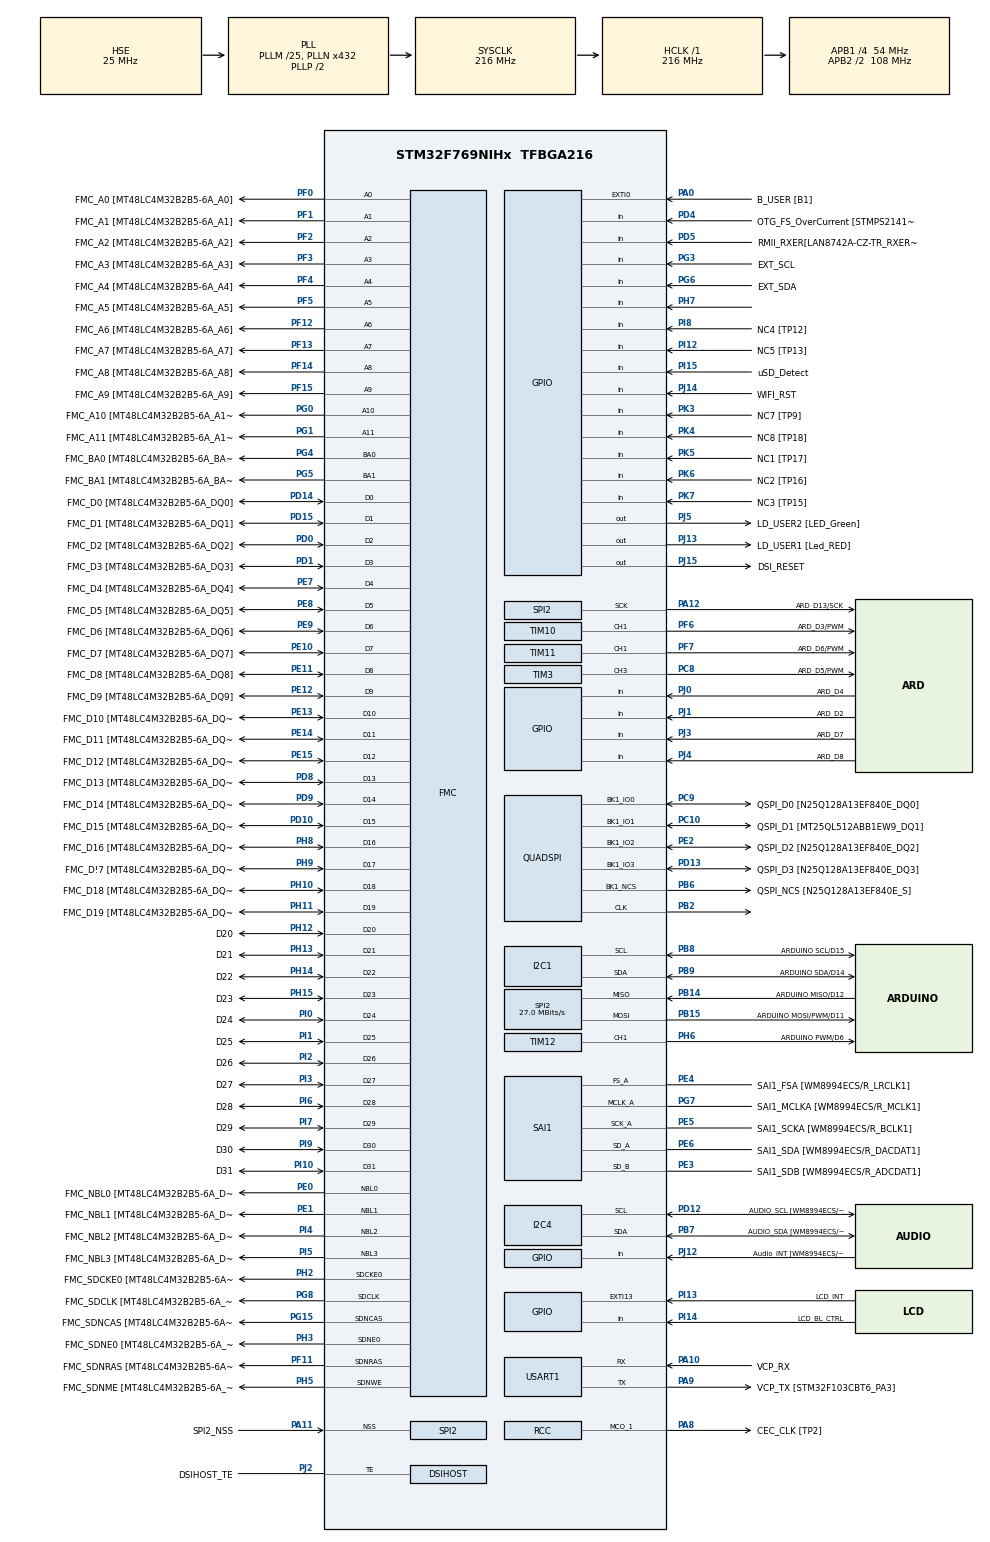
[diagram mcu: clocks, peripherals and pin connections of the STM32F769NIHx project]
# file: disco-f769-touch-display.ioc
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DSIHOST.CommandSize=400
DSIHOST.LPDcsLongWrite=DSI_LP_DLW_ENABLE
DSIHOST.LPDcsShortReadNoP=DSI_LP_DSR0P_ENABLE
DSIHOST.LPDcsShortWriteNoP=DSI_LP_DSW0P_ENABLE
DSIHOST.LPDcsShortWriteOneP=DSI_LP_DSW1P_ENABLE
DSIHOST.LPGenLongWrite=DSI_LP_GLW_ENABLE
DSIHOST.LPGenShortReadNoP=DSI_LP_GSR0P_ENABLE
DSIHOST.LPGenShortReadOneP=DSI_LP_GSR1P_ENABLE
DSIHOST.LPGenShortReadTwoP=DSI_LP_GSR2P_ENABLE
DSIHOST.LPGenShortWriteNoP=DSI_LP_GSW0P_ENABLE
DSIHOST.LPGenShortWriteOneP=DSI_LP_GSW1P_ENABLE
DSIHOST.LPGenShortWriteTwoP=DSI_LP_GSW2P_ENABLE
DSIHOST.LPMaxReadPacket=DSI_LP_MRDP_ENABLE
DSIHOST.NumberOfLanes=DSI_TWO_DATA_LANES
DSIHOST.StopWaitTime=10
DSIHOST.TEAcknowledgeRequest=DSI_TE_ACKNOWLEDGE_ENABLE
DSIHOST_CKN.GPIO_Label=DSI_CK_N
DSIHOST_CKN.Mode=DSIHost_Adapted_TE
DSIHOST_CKN.Signal=DSIHOST_CKN
DSIHOST_CKP.GPIO_Label=DSI_CK_P
DSIHOST_CKP.Mode=DSIHost_Adapted_TE
DSIHOST_CKP.Signal=DSIHOST_CKP
DSIHOST_D0N.GPIO_Label=DSI_D0_N
DSIHOST_D0N.Mode=DSIHost_Adapted_TE
DSIHOST_D0N.Signal=DSIHOST_D0N
DSIHOST_D0P.GPIO_Label=DSI_D0_p
DSIHOST_D0P.Mode=DSIHost_Adapted_TE
DSIHOST_D0P.Signal=DSIHOST_D0P
DSIHOST_D1N.GPIO_Label=DSI_D1_N
DSIHOST_D1N.Mode=DSIHost_Adapted_TE
DSIHOST_D1N.Signal=DSIHOST_D1N
DSIHOST_D1P.GPIO_Label=DSI_D1_P
DSIHOST_D1P.Mode=DSIHost_Adapted_TE
DSIHOST_D1P.Signal=DSIHOST_D1P
FMC.CASLatency1=FMC_SDRAM_CAS_LATENCY_3
FMC.ExitSelfRefreshDelay1=7
FMC.LoadToActiveDelay1=2
FMC.RCDDelay1=2
FMC.RPDelay1=2
FMC.RPDelay2=2
FMC.ReadBurst1=FMC_SDRAM_RBURST_ENABLE
FMC.ReadBurst2=FMC_SDRAM_RBURST_ENABLE
FMC.RowCycleDelay1=7
FMC.RowCycleDelay2=7
FMC.SDClockPeriod1=FMC_SDRAM_CLOCK_PERIOD_2
FMC.SDClockPeriod2=FMC_SDRAM_CLOCK_PERIOD_2
FMC.SelfRefreshTime1=4
FMC.WriteRecoveryTime1=3
I2C1.Timing=0x20404768
I2C4.Timing=0x20404768
LTDC.ActiveW=200
LTDC.Alpha_L0=255
LTDC.BlendingFactor1_L0=LTDC_BLENDING_FACTOR1_PAxCA
LTDC.BlendingFactor2_L0=LTDC_BLENDING_FACTOR2_PAxCA
LTDC.FBStartAdress_L0=0xC0000000
LTDC.HBP=1
LTDC.HFP=1
LTDC.HSync=1
LTDC.ImageHeight_L0=480
LTDC.ImageWidth_L0=200
LTDC.Layers=0
LTDC.PixelFormat_L0=LTDC_PIXEL_FORMAT_RGB565
LTDC.VBP=1
LTDC.VFP=1
LTDC.VSync=1
LTDC.WindowX1_L0=200
LTDC.WindowY1_L0=480
Mcu.Family=STM32F7
Mcu.Name=STM32F769NIHx
Mcu.Package=TFBGA216
NVIC.DMA2D_IRQn=true\:0\:0\:false\:false\:true\:true\:true\:true
NVIC.DSI_IRQn=true\:0\:0\:false\:false\:true\:true\:true\:true
NVIC.LTDC_IRQn=true\:0\:0\:false\:false\:true\:true\:true\:true
NVIC.PriorityGroup=NVIC_PRIORITYGROUP_4
NVIC.TIM6_DAC_IRQn=true\:15\:0\:false\:false\:true\:false\:true\:true
NVIC.TimeBase=TIM6_DAC_IRQn
NVIC.TimeBaseIP=TIM6
PA0/WKUP.GPIO_Label=B_USER [B1]
PA0/WKUP.Signal=GPXTI0
PA1.GPIO_Label=RMII_REF_CLK [LAN8742A-CZ-TR_REFCLK0]
PA1.Signal=ETH_REF_CLK
PA10.GPIO_Label=VCP_RX 
PA10.Mode=Asynchronous
PA10.Signal=USART1_RX
PA11.GPIO_Label=SPI2_NSS
PA11.Mode=NSS_Signal_Hard_Input
PA11.Signal=SPI2_NSS
PA12.GPIO_Label=ARD_D13/SCK
PA12.GPIO_Mode=GPIO_MODE_AF_PP
PA12.GPIO_PuPd=GPIO_NOPULL
PA12.GPIO_Speed=GPIO_SPEED_FREQ_LOW
PA12.Mode=Full_Duplex_Master
PA12.Signal=SPI2_SCK
PA13.GPIO_Label=SWDIO
PA13.Mode=Serial_Wire
PA13.Signal=SYS_JTMS-SWDIO
PA14.GPIO_Label=SWCLK
PA14.Mode=Serial_Wire
PA14.Signal=SYS_JTCK-SWCLK
PA15.GPIO_Label=CEC
PA15.Signal=CEC
PA2.GPIO_Label=RMII_MDIO [LAN8742A-CZ-TR_MDIO]
PA2.Signal=ETH_MDIO
PA3.GPIO_Label=ULPI_D0 [USB3320C-EZK_D0]
PA3.Signal=USB_OTG_HS_ULPI_D0
PA4.GPIO_Label=ARD_A1
PA4.Signal=ADCx_IN4
PA5.GPIO_Label=ULPI_CLK [USB3320C-EZK_CLKOUT]
PA5.Signal=USB_OTG_HS_ULPI_CK
PA6.GPIO_Label=ARD_A0
PA6.Signal=ADCx_IN6
PA7.GPIO_Label=RMII_CRS_DV [LAN8742A-CZ-TR_CRS_DV]
PA7.Signal=ETH_CRS_DV
PA8.GPIO_Label=CEC_CLK [TP2]
PA8.Mode=Clock-out-1
PA8.Signal=RCC_MCO_1
PA9.GPIO_Label=VCP_TX [STM32F103CBT6_PA3]
PA9.GPIO_Mode=GPIO_MODE_AF_PP
PA9.GPIO_PuPd=GPIO_NOPULL
PA9.GPIO_Speed=GPIO_SPEED_FREQ_LOW
PA9.Mode=Asynchronous
PA9.Signal=USART1_TX
PB0.GPIO_Label=ULPI_D1 [USB3320C-EZK_D1]
PB0.Signal=USB_OTG_HS_ULPI_D1
PB1.GPIO_Label=ULPI_D2 [USB3320C-EZK_D2]
PB1.Signal=USB_OTG_HS_ULPI_D2
PB10.GPIO_Label=ULPI_D3 [USB3320C-EZK_D3]
PB10.Signal=USB_OTG_HS_ULPI_D3
PB11.GPIO_Label=ULPI_D4 [USB3320C-EZK_D4]
PB11.Signal=USB_OTG_HS_ULPI_D4
PB12.GPIO_Label=ULPI_D5 [USB3320C-EZK_D5]
PB12.Signal=USB_OTG_HS_ULPI_D5
PB13.GPIO_Label=ULPI_D6 [USB3320C-EZK_D6]
PB13.Signal=USB_OTG_HS_ULPI_D6
PB14.GPIO_Label=ARDUINO MISO/D12
PB14.GPIO_Mode=GPIO_MODE_AF_PP
PB14.GPIO_PuPd=GPIO_NOPULL
PB14.GPIO_Speed=GPIO_SPEED_FREQ_LOW
PB14.Mode=Full_Duplex_Master
PB14.Signal=SPI2_MISO
PB15.GPIO_Label=ARDUINO MOSI/PWM/D11
PB15.GPIO_Mode=GPIO_MODE_AF_PP
PB15.GPIO_PuPd=GPIO_NOPULL
PB15.GPIO_Speed=GPIO_SPEED_FREQ_LOW
PB15.Mode=Full_Duplex_Master
PB15.Signal=SPI2_MOSI
PB2.Mode=Single Bank 1
PB2.Signal=QUADSPI_CLK
PB3.GPIO_Label=uSD_D2
PB3.Signal=SDMMC2_D2
PB4.GPIO_Label=uSD_D3
PB4.Signal=SDMMC2_D3
PB5.GPIO_Label=ULPI_D7 [USB3320C-EZK_D7]
PB5.Signal=USB_OTG_HS_ULPI_D7
PB6.GPIO_Label=QSPI_NCS [N25Q128A13EF840E_S]
PB6.Mode=Single Bank 1
PB6.Signal=QUADSPI_BK1_NCS
PB7.GPIO_Label=AUDIO_SDA [WM8994ECS/R_SDA]
PB7.GPIO_Pu=GPIO_PULLUP
PB7.Mode=I2C
PB7.Signal=I2C4_SDA
PB8.GPIO_Label=ARDUINO SCL/D15
PB8.GPIO_Mode=GPIO_MODE_AF_OD
PB8.GPIO_Pu=GPIO_PULLUP
PB8.GPIO_PuPd=GPIO_NOPULL
PB8.GPIO_Speed=GPIO_SPEED_FREQ_LOW
PB8.Mode=I2C
PB8.Signal=I2C1_SCL
PB9.GPIO_Label=ARDUINO SDA/D14
PB9.GPIO_Mode=GPIO_MODE_AF_OD
PB9.GPIO_Pu=GPIO_PULLUP
PB9.GPIO_PuPd=GPIO_NOPULL
PB9.GPIO_Speed=GPIO_SPEED_FREQ_LOW
PB9.Mode=I2C
PB9.Signal=I2C1_SDA
PC0.GPIO_Label=ULPI_STP [USB3320C-EZK_STP]
PC0.Signal=USB_OTG_HS_ULPI_STP
PC1.GPIO_Label=RMII_MDC [LAN8742A-CZ-TR_MDC]
PC1.Signal=ETH_MDC
PC10.GPIO_Label=QSPI_D1 [MT25QL512ABB1EW9_DQ1]
PC10.Mode=Single Bank 1
PC10.Signal=QUADSPI_BK1_IO1
PC11.GPIO_Label=DFSDM_DATIN5 [TP5]
PC11.Signal=S_DATAIN5DFSDM1
PC12.GPIO_Label=WIFI_RX
PC12.Signal=UART5_TX
PC13.Signal=RTC_OUT
PC14/OSC32_IN.GPIO_Label=RCC_OSC32_IN
PC14/OSC32_IN.Mode=LSE-External-Oscillator
PC14/OSC32_IN.Signal=RCC_OSC32_IN
PC15/OSC32_OUT.GPIO_Label=RCC_OSC32_OUT
PC15/OSC32_OUT.Mode=LSE-External-Oscillator
PC15/OSC32_OUT.Signal=RCC_OSC32_OUT
PC2.GPIO_Label=ARD_A2
PC2.Signal=ADCx_IN12
PC4.GPIO_Label=RMII_RXD0 [LAN8742A-CZ-TR_RXD0]
PC4.Signal=ETH_RXD0
PC5.GPIO_Label=RMII_RXD1 [LAN8742A-CZ-TR_RXD1]
PC5.Signal=ETH_RXD1
PC6.GPIO_Label=ARDUINO TX/D1
PC6.Signal=USART6_TX
PC7.GPIO_Label=ARD_D0/RX
PC7.Signal=USART6_RX
PC8.GPIO_Label=ARD_D5/PWM
PC8.Signal=S_TIM3_CH3
PC9.GPIO_Label=QSPI_D0 [N25Q128A13EF840E_DQ0]
PC9.Mode=Single Bank 1
PC9.Signal=QUADSPI_BK1_IO0
PD0.GPIO_Label=FMC_D2 [MT48LC4M32B2B5-6A_DQ2]
PD0.Signal=FMC_D2_DA2
PD1.GPIO_Label=FMC_D3 [MT48LC4M32B2B5-6A_DQ3]
PD1.Signal=FMC_D3_DA3
PD10.GPIO_Label=FMC_D15 [MT48LC4M32B2B5-6A_DQ15]
PD10.Signal=FMC_D15_DA15
PD11.GPIO_Label=SPDIF_TX [TP20]
PD11.Signal=SAI2_SD_A
PD12.GPIO_Label=AUDIO_SCL [WM8994ECS/R_SCLK]
PD12.GPIO_Pu=GPIO_PULLUP
PD12.Mode=I2C
PD12.Signal=I2C4_SCL
PD13.GPIO_Label=QSPI_D3 [N25Q128A13EF840E_DQ3]
PD13.Mode=Single Bank 1
PD13.Signal=QUADSPI_BK1_IO3
PD14.GPIO_Label=FMC_D0 [MT48LC4M32B2B5-6A_DQ0]
PD14.Signal=FMC_D0_DA0
PD15.GPIO_Label=FMC_D1 [MT48LC4M32B2B5-6A_DQ1]
PD15.Signal=FMC_D1_DA1
PD2.GPIO_Label=WIFI_TX
PD2.Signal=UART5_RX
PD3.GPIO_Label=DFSDM_CKOUT [TP102]
PD3.Signal=S_CKOUTDFSDM1
PD4.GPIO_Label=OTG_FS_OverCurrent [STMPS2141STR_Fault]
PD4.Signal=GPIO_Input
PD5.GPIO_Label=RMII_RXER[LAN8742A-CZ-TR_RXERR]
PD5.Signal=GPIO_Input
PD6.GPIO_Label=uSD_CLK
PD6.Signal=SDMMC2_CK
PD7.GPIO_Label=uSD_CMD
PD7.Signal=SDMMC2_CMD
PD8.GPIO_Label=FMC_D13 [MT48LC4M32B2B5-6A_DQ13]
PD8.Signal=FMC_D13_DA13
PD9.GPIO_Label=FMC_D14 [MT48LC4M32B2B5-6A_DQ14]
PD9.Signal=FMC_D14_DA14
PE0.GPIO_Label=FMC_NBL0 [MT48LC4M32B2B5-6A_DQM0]
PE0.Signal=FMC_NBL0
PE1.GPIO_Label=FMC_NBL1 [MT48LC4M32B2B5-6A_DQM1]
PE1.Signal=FMC_NBL1
PE10.GPIO_Label=FMC_D7 [MT48LC4M32B2B5-6A_DQ7]
PE10.Signal=FMC_D7_DA7
PE11.GPIO_Label=FMC_D8 [MT48LC4M32B2B5-6A_DQ8]
PE11.Signal=FMC_D8_DA8
PE12.GPIO_Label=FMC_D9 [MT48LC4M32B2B5-6A_DQ9]
PE12.Signal=FMC_D9_DA9
PE13.GPIO_Label=FMC_D10 [MT48LC4M32B2B5-6A_DQ10]
PE13.Signal=FMC_D10_DA10
PE14.GPIO_Label=FMC_D11 [MT48LC4M32B2B5-6A_DQ11]
PE14.Signal=FMC_D11_DA11
PE15.GPIO_Label=FMC_D12 [MT48LC4M32B2B5-6A_DQ12]
PE15.Signal=FMC_D12_DA12
PE2.GPIO_Label=QSPI_D2 [N25Q128A13EF840E_DQ2]
PE2.Mode=Single Bank 1
PE2.Signal=QUADSPI_BK1_IO2
PE3.GPIO_Label=SAI1_SDB [WM8994ECS/R_ADCDAT1]
PE3.Mode=SAI_B_SyncSlave
PE3.Signal=SAI1_SD_B
PE4.GPIO_Label=SAI1_FSA [WM8994ECS/R_LRCLK1]
PE4.Mode=SAI_A_MasterWithClock
PE4.Signal=SAI1_FS_A
PE5.GPIO_Label=SAI1_SCKA [WM8994ECS/R_BCLK1]
PE5.Mode=SAI_A_MasterWithClock
PE5.Signal=SAI1_SCK_A
PE6.GPIO_Label=SAI1_SDA [WM8994ECS/R_DACDAT1]
PE6.Mode=SAI_A_MasterWithClock
PE6.Signal=SAI1_SD_A
PE7.GPIO_Label=FMC_D4 [MT48LC4M32B2B5-6A_DQ4]
PE7.Signal=FMC_D4_DA4
PE8.GPIO_Label=FMC_D5 [MT48LC4M32B2B5-6A_DQ5]
PE8.Signal=FMC_D5_DA5
PE9.GPIO_Label=FMC_D6 [MT48LC4M32B2B5-6A_DQ6]
PE9.Signal=FMC_D6_DA6
PF0.GPIO_Label=FMC_A0 [MT48LC4M32B2B5-6A_A0]
PF0.Signal=FMC_A0
PF1.GPIO_Label=FMC_A1 [MT48LC4M32B2B5-6A_A1]
PF1.Signal=FMC_A1
PF10.GPIO_Label=ARDUINO A1
PF10.GPIO_Mode=GPIO_MODE_ANALOG
PF10.GPIO_PuPd=GPIO_NOPULL
PF10.Signal=ADC3_IN8
PF11.GPIO_Label=FMC_SDNRAS [MT48LC4M32B2B5-6A_RAS]
PF11.Signal=FMC_SDNRAS
PF12.GPIO_Label=FMC_A6 [MT48LC4M32B2B5-6A_A6]
PF12.Signal=FMC_A6
PF13.GPIO_Label=FMC_A7 [MT48LC4M32B2B5-6A_A7]
PF13.Signal=FMC_A7
PF14.GPIO_Label=FMC_A8 [MT48LC4M32B2B5-6A_A8]
PF14.Signal=FMC_A8
PF15.GPIO_Label=FMC_A9 [MT48LC4M32B2B5-6A_A9]
PF15.Signal=FMC_A9
PF2.GPIO_Label=FMC_A2 [MT48LC4M32B2B5-6A_A2]
PF2.Signal=FMC_A2
PF3.GPIO_Label=FMC_A3 [MT48LC4M32B2B5-6A_A3]
PF3.Signal=FMC_A3
PF4.GPIO_Label=FMC_A4 [MT48LC4M32B2B5-6A_A4]
PF4.Signal=FMC_A4
PF5.GPIO_Label=FMC_A5 [MT48LC4M32B2B5-6A_A5]
PF5.Signal=FMC_A5
PF6.GPIO_Label=ARD_D3/PWM
PF6.Signal=S_TIM10_CH1
PF7.GPIO_Label=ARD_D6/PWM
PF7.Signal=S_TIM11_CH1
PF8.GPIO_Label=ARDUINO A3
PF8.GPIO_Mode=GPIO_MODE_ANALOG
PF8.GPIO_PuPd=GPIO_NOPULL
PF8.Signal=ADC3_IN6
PF9.GPIO_Label=ARDUINO A2
PF9.GPIO_Mode=GPIO_MODE_ANALOG
PF9.GPIO_PuPd=GPIO_NOPULL
PF9.Signal=ADC3_IN7
PG0.GPIO_Label=FMC_A10 [MT48LC4M32B2B5-6A_A10]
PG0.Signal=FMC_A10
PG1.GPIO_Label=FMC_A11 [MT48LC4M32B2B5-6A_A11]
PG1.Signal=FMC_A11
PG10.GPIO_Label=uSD_D1
PG10.Signal=SDMMC2_D1
PG11.GPIO_Label=RMII_TX_EN [LAN8742A-CZ-TR_TXEN]
PG11.Signal=ETH_TX_EN
PG12.GPIO_Label=SPDIF_RX [74LVC1G04SE_4]
PG12.Signal=SPDIFRX_IN1
PG13.GPIO_Label=RMII_TXD0 [LAN8742A-CZ-TR_TXD0]
PG13.Signal=ETH_TXD0
PG14.GPIO_Label=RMII_TXD1 [LAN8742A-CZ-TR_TXD1]
PG14.Signal=ETH_TXD1
PG15.GPIO_Label=FMC_SDNCAS [MT48LC4M32B2B5-6A_CAS]
PG15.Signal=FMC_SDNCAS
PG2.GPIO_Label=FMC_A12
PG2.Signal=FMC_A12
PG3.GPIO_Label=EXT_SCL
PG3.Signal=GPIO_Input
PG4.GPIO_Label=FMC_BA0 [MT48LC4M32B2B5-6A_BA0]
PG4.Signal=FMC_A14_BA0
PG5.GPIO_Label=FMC_BA1 [MT48LC4M32B2B5-6A_BA1]
PG5.Signal=FMC_A15_BA1
PG6.GPIO_Label=EXT_SDA
PG6.Signal=GPIO_Input
PG7.GPIO_Label=SAI1_MCLKA [WM8994ECS/R_MCLK1]
PG7.Mode=SAI_A_MasterWithClock
PG7.Signal=SAI1_MCLK_A
PG8.GPIO_Label=FMC_SDCLK [MT48LC4M32B2B5-6A_CLK]
PG8.Signal=FMC_SDCLK
PG9.GPIO_Label=uSD_D0
PG9.Signal=SDMMC2_D0
PH0/OSC_IN.GPIO_Label=OSC_25M [NZ2520SB-25.00M_OUT]
PH0/OSC_IN.Mode=HSE-External-Oscillator
PH0/OSC_IN.Signal=RCC_OSC_IN
PH1/OSC_OUT.Mode=HSE-External-Oscillator
PH1/OSC_OUT.Signal=RCC_OSC_OUT
PH10.GPIO_Label=FMC_D18 [MT48LC4M32B2B5-6A_DQ18]
PH10.Signal=FMC_D18
PH11.GPIO_Label=FMC_D19 [MT48LC4M32B2B5-6A_DQ19]
PH11.Signal=FMC_D19
PH12.GPIO_Label=D20
PH12.Signal=FMC_D20
PH13.GPIO_Label=D21
PH13.Signal=FMC_D21
PH14.GPIO_Label=D22
PH14.Signal=FMC_D22
PH15.GPIO_Label=D23
PH15.Signal=FMC_D23
PH2.GPIO_Label=FMC_SDCKE0 [MT48LC4M32B2B5-6A_CKE]
PH2.Mode=SdramChipSelect1_1
PH2.Signal=FMC_SDCKE0
PH3.GPIO_Label=FMC_SDNE0 [MT48LC4M32B2B5-6A_CS]
PH3.Mode=SdramChipSelect1_1
PH3.Signal=FMC_SDNE0
PH4.GPIO_Label=ULPI_NXT [USB3320C-EZK_NXT]
PH4.Signal=USB_OTG_HS_ULPI_NXT
PH5.GPIO_Label=FMC_SDNME [MT48LC4M32B2B5-6A_WE]
PH5.Signal=FMC_SDNWE
PH6.GPIO_Label=ARDUINO PWM/D6
PH6.Signal=S_TIM12_CH1
PH7.Signal=GPIO_Input
PH8.GPIO_Label=FMC_D16 [MT48LC4M32B2B5-6A_DQ16]
PH8.Signal=FMC_D16
PH9.GPIO_Label=FMC_D\!7 [MT48LC4M32B2B5-6A_DQ17]
PH9.Signal=FMC_D17
PI0.GPIO_Label=D24
PI0.Signal=FMC_D24
PI1.GPIO_Label=D25
PI1.Signal=FMC_D25
PI10.GPIO_Label=D31
PI10.Signal=FMC_D31
PI11.GPIO_Label=ULPI_DIR [USB3320C-EZK_DIR]
PI11.Signal=USB_OTG_HS_ULPI_DIR
PI12.GPIO_Label=NC5 [TP13]
PI12.Signal=GPIO_Input
PI13.GPIO_Label=LCD_INT
PI13.GPIO_ModeDefaultEXTI=GPIO_MODE_EVT_RISING
PI13.Signal=GPXTI13
PI14.GPIO_Label=LCD_BL_CTRL
PI14.Signal=GPIO_Input
PI15.GPIO_Label=uSD_Detect
PI15.Signal=GPIO_Input
PI2.GPIO_Label=D26
PI2.Signal=FMC_D26
PI3.GPIO_Label=D27
PI3.Signal=FMC_D27
PI4.GPIO_Label=FMC_NBL2 [MT48LC4M32B2B5-6A_DQM2]
PI4.Signal=FMC_NBL2
PI5.GPIO_Label=FMC_NBL3 [MT48LC4M32B2B5-6A_DQM3]
PI5.Signal=FMC_NBL3
PI6.GPIO_Label=D28
PI6.Signal=FMC_D28
PI7.GPIO_Label=D29
PI7.Signal=FMC_D29
PI8.GPIO_Label=NC4 [TP12]
PI8.Signal=GPIO_Input
PI9.GPIO_Label=D30
PI9.Signal=FMC_D30
PJ0.GPIO_Label=ARD_D4
PJ0.Signal=GPIO_Input
PJ1.GPIO_Label=ARD_D2
PJ1.Signal=GPIO_Input
PJ12.GPIO_Label=Audio_INT [WM8994ECS/R_GPIO1]
PJ12.Signal=GPIO_Input
PJ13.GPIO_Label=LD_USER1 [Led_RED]
PJ13.Signal=GPIO_Output
PJ14.GPIO_Label=WIFI_RST
PJ14.Signal=GPIO_Input
PJ15.GPIO_Label=DSI_RESET
PJ15.Signal=GPIO_Output
PJ2.GPIO_Label=DSIHOST_TE
PJ2.Mode=DSIHost_Adapted_TE
PJ2.Signal=DSIHOST_TE
PJ3.GPIO_Label=ARD_D7
PJ3.Signal=GPIO_Input
PJ4.GPIO_Label=ARD_D8
PJ4.Signal=GPIO_Input
PJ5.GPIO_Label=LD_USER2 [LED_Green]
PJ5.Signal=GPIO_Output
PK3.GPIO_Label=NC7 [TP9]
PK3.Signal=GPIO_Input
PK4.GPIO_Label=NC8 [TP18]
PK4.Signal=GPIO_Input
PK5.GPIO_Label=NC1 [TP17]
PK5.Signal=GPIO_Input
PK6.GPIO_Label=NC2 [TP16]
PK6.Signal=GPIO_Input
PK7.GPIO_Label=NC3 [TP15]
PK7.Signal=GPIO_Input
ProjectManager.HeapSize=0x200
ProjectManager.StackSize=0x400
ProjectManager.TargetToolchain=STM32CubeIDE
QUADSPI.ChipSelectHighTime=QSPI_CS_HIGH_TIME_4_CYCLE
QUADSPI.ClockPrescaler=1
QUADSPI.FifoThreshold=16
QUADSPI.FlashSize=26
QUADSPI.SampleShifting=QSPI_SAMPLE_SHIFTING_HALFCYCLE
RCC.AHBFreq_Value=216000000
RCC.APB1CLKDivider=RCC_HCLK_DIV4
RCC.APB1Freq_Value=54000000
RCC.APB1TimFreq_Value=108000000
RCC.APB2CLKDivider=RCC_HCLK_DIV2
RCC.APB2Freq_Value=108000000
RCC.APB2TimFreq_Value=216000000
RCC.CortexFreq_Value=216000000
RCC.HCLKFreq_Value=216000000
RCC.HSE_VALUE=25000000
RCC.HSI_VALUE=16000000
RCC.PLL48CLockSelection=RCC_CLK48SOURCE_PLLSAIP
RCC.PLLM=25
RCC.PLLN=432
RCC.PLLQ=4
RCC.PLLSAIP=RCC_PLLSAIP_DIV4
RCC.PLLSAIQ=3
RCC.PLLSourceVirtual=RCC_PLLSOURCE_HSE
RCC.SDMMC2ClockSelection=RCC_SDMMC2CLKSOURCE_CLK48
RCC.SYSCLKFreq_VALUE=216000000
RCC.SYSCLKSource=RCC_SYSCLKSOURCE_PLLCLK
RCC.USBFreq_Value=48000000
RCC.VCOOutputFreq_Value=432000000
SAI1.ErrorAudioFreq-SAI_A_MasterWithClock=30.2 %
SAI1.Instance-SAI_A_MasterWithClock=SAI$Index_Block_A
SAI1.Instance-SAI_B_SyncSlave=SAI$Index_Block_B
SAI1.MClockEnable-SAI_A_MasterWithClock=SAI_MASTERCLOCK_ENABLE
SAI1.RealAudioFreq-SAI_A_MasterWithClock=250.0 KHz
SAI1.VirtualMode-SAI_A_MasterWithClock=VM_MASTER
SAI1.VirtualMode-SAI_B_SyncSlave=VM_SLAVE
SH.ADCx_IN12.0=ADC1_IN12
SH.ADCx_IN4.0=ADC1_IN4
SH.ADCx_IN6.0=ADC1_IN6
SH.FMC_A0.0=FMC_A0,12b-sda1
SH.FMC_A1.0=FMC_A1,12b-sda1
SH.FMC_A10.0=FMC_A10,12b-sda1
SH.FMC_A11.0=FMC_A11,12b-sda1
SH.FMC_A12.0=FMC_A12
SH.FMC_A14_BA0.0=FMC_BA0,FourSdramBanks1
SH.FMC_A15_BA1.0=FMC_BA1,FourSdramBanks1
SH.FMC_A2.0=FMC_A2,12b-sda1
SH.FMC_A3.0=FMC_A3,12b-sda1
SH.FMC_A4.0=FMC_A4,12b-sda1
SH.FMC_A5.0=FMC_A5,12b-sda1
SH.FMC_A6.0=FMC_A6,12b-sda1
SH.FMC_A7.0=FMC_A7,12b-sda1
SH.FMC_A8.0=FMC_A8,12b-sda1
SH.FMC_A9.0=FMC_A9,12b-sda1
SH.FMC_D0_DA0.0=FMC_D0,sd-32b-d1
SH.FMC_D10_DA10.0=FMC_D10,sd-32b-d1
SH.FMC_D11_DA11.0=FMC_D11,sd-32b-d1
SH.FMC_D12_DA12.0=FMC_D12,sd-32b-d1
SH.FMC_D13_DA13.0=FMC_D13,sd-32b-d1
SH.FMC_D14_DA14.0=FMC_D14,sd-32b-d1
SH.FMC_D15_DA15.0=FMC_D15,sd-32b-d1
SH.FMC_D16.0=FMC_D16,sd-32b-d1
SH.FMC_D17.0=FMC_D17,sd-32b-d1
SH.FMC_D18.0=FMC_D18,sd-32b-d1
SH.FMC_D19.0=FMC_D19,sd-32b-d1
SH.FMC_D1_DA1.0=FMC_D1,sd-32b-d1
SH.FMC_D20.0=FMC_D20,sd-32b-d1
SH.FMC_D21.0=FMC_D21,sd-32b-d1
SH.FMC_D22.0=FMC_D22,sd-32b-d1
SH.FMC_D23.0=FMC_D23,sd-32b-d1
SH.FMC_D24.0=FMC_D24,sd-32b-d1
SH.FMC_D25.0=FMC_D25,sd-32b-d1
SH.FMC_D26.0=FMC_D26,sd-32b-d1
SH.FMC_D27.0=FMC_D27,sd-32b-d1
SH.FMC_D28.0=FMC_D28,sd-32b-d1
SH.FMC_D29.0=FMC_D29,sd-32b-d1
SH.FMC_D2_DA2.0=FMC_D2,sd-32b-d1
SH.FMC_D30.0=FMC_D30,sd-32b-d1
SH.FMC_D31.0=FMC_D31,sd-32b-d1
SH.FMC_D3_DA3.0=FMC_D3,sd-32b-d1
SH.FMC_D4_DA4.0=FMC_D4,sd-32b-d1
SH.FMC_D5_DA5.0=FMC_D5,sd-32b-d1
SH.FMC_D6_DA6.0=FMC_D6,sd-32b-d1
SH.FMC_D7_DA7.0=FMC_D7,sd-32b-d1
SH.FMC_D8_DA8.0=FMC_D8,sd-32b-d1
SH.FMC_D9_DA9.0=FMC_D9,sd-32b-d1
SH.FMC_NBL0.0=FMC_NBL0,Sd4ByteEnable1
SH.FMC_NBL1.0=FMC_NBL1,Sd4ByteEnable1
SH.FMC_NBL2.0=FMC_NBL2,Sd4ByteEnable1
SH.FMC_NBL3.0=FMC_NBL3,Sd4ByteEnable1
SH.FMC_SDCLK.0=FMC_SDCLK,12b-sda1
SH.FMC_SDNCAS.0=FMC_SDNCAS,12b-sda1
SH.FMC_SDNRAS.0=FMC_SDNRAS,12b-sda1
SH.FMC_SDNWE.0=FMC_SDNWE,12b-sda1
SH.S_CKOUTDFSDM1.0=DFSDM1_CKOUT
SH.S_DATAIN5DFSDM1.0=DFSDM1_DATIN5
SH.S_TIM10_CH1.0=TIM10_CH1,PWM Generation1 CH1
SH.S_TIM11_CH1.0=TIM11_CH1,PWM Generation1 CH1
SH.S_TIM12_CH1.0=TIM12_CH1,PWM Generation1 CH1
SH.S_TIM3_CH3.0=TIM3_CH3,PWM Generation3 CH3
SPI2.BaudRatePrescaler=SPI_BAUDRATEPRESCALER_2
SPI2.CalculateBaudRate=27.0 MBits/s
SPI2.Direction=SPI_DIRECTION_2LINES
SPI2.Mode=SPI_MODE_MASTER
SPI2.VirtualNSS=VM_NSSHARD
SPI2.VirtualType=VM_MASTER
TIM10.Channel=TIM_CHANNEL_1
TIM11.Channel=TIM_CHANNEL_1
TIM12.Channel-PWM\ Generation1\ CH1=TIM_CHANNEL_1
TIM3.Channel-PWM\ Generation3\ CH3=TIM_CHANNEL_3
USART1.VirtualMode-Asynchronous=VM_ASYNC
VP_CRC_VS_CRC.Mode=CRC_Activate
VP_DMA2D_VS_DMA2D.Mode=DMA2D_Activate
VP_LTDC_DSIMode.Mode=RGB888
VP_SYS_VS_tim6.Mode=TIM6
VP_TIM10_VS_ClockSourceINT.Mode=Enable_Timer
VP_TIM11_VS_ClockSourceINT.Mode=Enable_Timer
VP_TIM1_VS_ClockSourceINT.Mode=Internal
board=STM32F769I-DISCO

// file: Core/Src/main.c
/* USER CODE BEGIN Header */
/**
  ******************************************************************************
  * @file           : main.c
  * @brief          : Main program body
  ******************************************************************************
  * @attention
  *
  * Copyright (c) 2025 STMicroelectronics.
  * All rights reserved.
  *
  * This software is licensed under terms that can be found in the LICENSE file
  * in the root directory of this software component.
  * If no LICENSE file comes with this software, it is provided AS-IS.
  *
  ******************************************************************************
  */
/* USER CODE END Header */
#include "main.h"

/* USER CODE BEGIN Includes */
#include <stdio.h>

/* USER CODE END Includes */

CRC_HandleTypeDef hcrc;

DMA2D_HandleTypeDef hdma2d;

DSI_HandleTypeDef hdsi;

I2C_HandleTypeDef hi2c1;
I2C_HandleTypeDef hi2c4;

LTDC_HandleTypeDef hltdc;

QSPI_HandleTypeDef hqspi;

SAI_HandleTypeDef hsai_BlockA1;
SAI_HandleTypeDef hsai_BlockB1;

SPI_HandleTypeDef hspi2;

TIM_HandleTypeDef htim1;
TIM_HandleTypeDef htim3;
TIM_HandleTypeDef htim10;
TIM_HandleTypeDef htim11;
TIM_HandleTypeDef htim12;

UART_HandleTypeDef huart1;

SDRAM_HandleTypeDef hsdram1;

/* USER CODE BEGIN PV */

// Touch screen status
TS_StateTypeDef TS_State = {0};
uint32_t ts_status = TS_OK;

/* USER CODE END PV */

void SystemClock_Config(void);
void PeriphCommonClock_Config(void);
static void MX_GPIO_Init(void);
static void MX_CRC_Init(void);
static void MX_DMA2D_Init(void);
static void MX_DSIHOST_DSI_Init(void);
static void MX_FMC_Init(void);
static void MX_I2C1_Init(void);
static void MX_I2C4_Init(void);
static void MX_LTDC_Init(void);
static void MX_QUADSPI_Init(void);
static void MX_SAI1_Init(void);
static void MX_SPI2_Init(void);
static void MX_TIM1_Init(void);
static void MX_TIM3_Init(void);
static void MX_TIM10_Init(void);
static void MX_TIM11_Init(void);
static void MX_TIM12_Init(void);
static void MX_USART1_UART_Init(void);

/* USER CODE BEGIN 0 */
void OnError_Handler(uint32_t condition) {

  if (condition) {
    BSP_LED_On(LED1);
    while(1) {;}
  }
}
/* USER CODE END 0 */

int main(void)
{

  /* USER CODE BEGIN 1 */
	char buffer[50];

  /* USER CODE END 1 */

  /* MCU Configuration--------------------------------------------------------*/

  /* Reset of all peripherals, Initializes the Flash interface and the Systick. */
  HAL_Init();

  /* Configure the system clock */
  SystemClock_Config();

  /* Configure the peripherals common clocks */
  PeriphCommonClock_Config();

  /* Initialize all configured peripherals */
  MX_GPIO_Init();
  MX_CRC_Init();
  MX_DMA2D_Init();
  MX_DSIHOST_DSI_Init();
  MX_FMC_Init();
  MX_I2C1_Init();
  MX_I2C4_Init();
  MX_LTDC_Init();
  MX_QUADSPI_Init();
  MX_SAI1_Init();
  MX_SPI2_Init();
  MX_TIM1_Init();
  MX_TIM3_Init();
  MX_TIM10_Init();
  MX_TIM11_Init();
  MX_TIM12_Init();
  MX_USART1_UART_Init();
  /* USER CODE BEGIN 2 */

  uint8_t bsp_status = 0;
  bsp_status = BSP_QSPI_Init();
  OnError_Handler(bsp_status != QSPI_OK);

  bsp_status = BSP_QSPI_EnableMemoryMappedMode();
  OnError_Handler(bsp_status != QSPI_OK);
  HAL_NVIC_DisableIRQ(QUADSPI_IRQn);

  uint8_t lcd_status = LCD_OK;
  lcd_status = BSP_LCD_Init();
  OnError_Handler(lcd_status != LCD_OK);

  BSP_LCD_SetBrightness(100);
  BSP_LCD_LayerDefaultInit(0, LCD_FB_START_ADDRESS);

  // White font on black background
  //BSP_LCD_Clear(LCD_COLOR_WHITE);
  BSP_LCD_SetBackColor(LCD_COLOR_BLACK);
  BSP_LCD_SetTextColor(LCD_COLOR_WHITE);

  BSP_LCD_SetFont(&Font24);

  BSP_LCD_DisplayStringAt(0, LINE(1), (uint8_t *)"STM32F769i Discovery Kit", CENTER_MODE);
  BSP_LCD_DisplayStringAt(0, LINE(2), (uint8_t *)"Touch-Display Demo", CENTER_MODE);

  // initialize touch display
  ts_status = BSP_TS_Init(BSP_LCD_GetXSize(), BSP_LCD_GetYSize());

  if (ts_status == TS_OK) {
  	printf("Touch screen is go\r\n");
  	printf("x-size: %ld, y-size: %ld\r\n", BSP_LCD_GetXSize(), BSP_LCD_GetYSize());
  }

  BSP_LCD_DisplayStringAt(30, LINE(5), (uint8_t*)"Touch display coords:", LEFT_MODE);

  /* USER CODE END 2 */

  /* Infinite loop */
  while (1)
  {

    /* USER CODE BEGIN 3 */
	  ts_status = BSP_TS_GetState(&TS_State);
	  if (TS_State.touchDetected) {

	    uint16_t xAxis = TS_State.touchX[0];
	  	uint16_t yAxis = TS_State.touchY[0];

	  	// print coords via uart
	  	printf("%d, %d\r\n", xAxis, yAxis);

	  	// display coords on screen
	  	sprintf(buffer, "Touch display coords: x=%3d, y=%3d", xAxis, yAxis);
	  	BSP_LCD_DisplayStringAt(30, LINE(5) , (uint8_t*)&buffer, LEFT_MODE);
	  }
  }
  /* USER CODE END 3 */
}

void SystemClock_Config(void)
{
  RCC_OscInitTypeDef RCC_OscInitStruct = {0};
  RCC_ClkInitTypeDef RCC_ClkInitStruct = {0};

  /** Configure LSE Drive Capability
  */
  HAL_PWR_EnableBkUpAccess();

  /** Configure the main internal regulator output voltage
  */
  __HAL_RCC_PWR_CLK_ENABLE();
  __HAL_PWR_VOLTAGESCALING_CONFIG(PWR_REGULATOR_VOLTAGE_SCALE1);

  /** Initializes the RCC Oscillators according to the specified parameters
  * in the RCC_OscInitTypeDef structure.
  */
  RCC_OscInitStruct.OscillatorType = RCC_OSCILLATORTYPE_HSI|RCC_OSCILLATORTYPE_HSE;
  RCC_OscInitStruct.HSEState = RCC_HSE_ON;
  RCC_OscInitStruct.HSIState = RCC_HSI_ON;
  RCC_OscInitStruct.HSICalibrationValue = RCC_HSICALIBRATION_DEFAULT;
  RCC_OscInitStruct.PLL.PLLState = RCC_PLL_ON;
  RCC_OscInitStruct.PLL.PLLSource = RCC_PLLSOURCE_HSE;
  RCC_OscInitStruct.PLL.PLLM = 25;
  RCC_OscInitStruct.PLL.PLLN = 432;
  RCC_OscInitStruct.PLL.PLLP = RCC_PLLP_DIV2;
  RCC_OscInitStruct.PLL.PLLQ = 4;
  RCC_OscInitStruct.PLL.PLLR = 2;
  if (HAL_RCC_OscConfig(&RCC_OscInitStruct) != HAL_OK)
  {
    Error_Handler();
  }

  /** Activate the Over-Drive mode
  */
  if (HAL_PWREx_EnableOverDrive() != HAL_OK)
  {
    Error_Handler();
  }

  /** Initializes the CPU, AHB and APB buses clocks
  */
  RCC_ClkInitStruct.ClockType = RCC_CLOCKTYPE_HCLK|RCC_CLOCKTYPE_SYSCLK
                              |RCC_CLOCKTYPE_PCLK1|RCC_CLOCKTYPE_PCLK2;
  RCC_ClkInitStruct.SYSCLKSource = RCC_SYSCLKSOURCE_PLLCLK;
  RCC_ClkInitStruct.AHBCLKDivider = RCC_SYSCLK_DIV1;
  RCC_ClkInitStruct.APB1CLKDivider = RCC_HCLK_DIV4;
  RCC_ClkInitStruct.APB2CLKDivider = RCC_HCLK_DIV2;

  if (HAL_RCC_ClockConfig(&RCC_ClkInitStruct, FLASH_LATENCY_7) != HAL_OK)
  {
    Error_Handler();
  }
  HAL_RCC_MCOConfig(RCC_MCO1, RCC_MCO1SOURCE_HSI, RCC_MCODIV_1);
}

void PeriphCommonClock_Config(void)
{
  RCC_PeriphCLKInitTypeDef PeriphClkInitStruct = {0};

  /** Initializes the peripherals clock
  */
  PeriphClkInitStruct.PeriphClockSelection = RCC_PERIPHCLK_LTDC|RCC_PERIPHCLK_SAI1;
  PeriphClkInitStruct.PLLSAI.PLLSAIN = 192;
  PeriphClkInitStruct.PLLSAI.PLLSAIR = 2;
  PeriphClkInitStruct.PLLSAI.PLLSAIQ = 3;
  PeriphClkInitStruct.PLLSAI.PLLSAIP = RCC_PLLSAIP_DIV4;
  PeriphClkInitStruct.PLLSAIDivQ = 1;
  PeriphClkInitStruct.PLLSAIDivR = RCC_PLLSAIDIVR_2;
  PeriphClkInitStruct.Sai1ClockSelection = RCC_SAI1CLKSOURCE_PLLSAI;
  if (HAL_RCCEx_PeriphCLKConfig(&PeriphClkInitStruct) != HAL_OK)
  {
    Error_Handler();
  }
}

static void MX_CRC_Init(void)
{

  hcrc.Instance = CRC;
  hcrc.Init.DefaultPolynomialUse = DEFAULT_POLYNOMIAL_ENABLE;
  hcrc.Init.DefaultInitValueUse = DEFAULT_INIT_VALUE_ENABLE;
  hcrc.Init.InputDataInversionMode = CRC_INPUTDATA_INVERSION_NONE;
  hcrc.Init.OutputDataInversionMode = CRC_OUTPUTDATA_INVERSION_DISABLE;
  hcrc.InputDataFormat = CRC_INPUTDATA_FORMAT_BYTES;
  if (HAL_CRC_Init(&hcrc) != HAL_OK)
  {
    Error_Handler();
  }

}

static void MX_DMA2D_Init(void)
{

  hdma2d.Instance = DMA2D;
  hdma2d.Init.Mode = DMA2D_M2M;
  hdma2d.Init.ColorMode = DMA2D_OUTPUT_ARGB8888;
  hdma2d.Init.OutputOffset = 0;
  hdma2d.LayerCfg[1].InputOffset = 0;
  hdma2d.LayerCfg[1].InputColorMode = DMA2D_INPUT_ARGB8888;
  hdma2d.LayerCfg[1].AlphaMode = DMA2D_NO_MODIF_ALPHA;
  hdma2d.LayerCfg[1].InputAlpha = 0;
  hdma2d.LayerCfg[1].AlphaInverted = DMA2D_REGULAR_ALPHA;
  hdma2d.LayerCfg[1].RedBlueSwap = DMA2D_RB_REGULAR;
  if (HAL_DMA2D_Init(&hdma2d) != HAL_OK)
  {
    Error_Handler();
  }
  if (HAL_DMA2D_ConfigLayer(&hdma2d, 1) != HAL_OK)
  {
    Error_Handler();
  }

}

static void MX_DSIHOST_DSI_Init(void)
{

  DSI_PLLInitTypeDef PLLInit = {0};
  DSI_HOST_TimeoutTypeDef HostTimeouts = {0};
  DSI_PHY_TimerTypeDef PhyTimings = {0};
  DSI_LPCmdTypeDef LPCmd = {0};
  DSI_CmdCfgTypeDef CmdCfg = {0};

  hdsi.Instance = DSI;
  hdsi.Init.AutomaticClockLaneControl = DSI_AUTO_CLK_LANE_CTRL_DISABLE;
  hdsi.Init.TXEscapeCkdiv = 4;
  hdsi.Init.NumberOfLanes = DSI_TWO_DATA_LANES;
  PLLInit.PLLNDIV = 20;
  PLLInit.PLLIDF = DSI_PLL_IN_DIV1;
  PLLInit.PLLODF = DSI_PLL_OUT_DIV1;
  if (HAL_DSI_Init(&hdsi, &PLLInit) != HAL_OK)
  {
    Error_Handler();
  }
  HostTimeouts.TimeoutCkdiv = 1;
  HostTimeouts.HighSpeedTransmissionTimeout = 0;
  HostTimeouts.LowPowerReceptionTimeout = 0;
  HostTimeouts.HighSpeedReadTimeout = 0;
  HostTimeouts.LowPowerReadTimeout = 0;
  HostTimeouts.HighSpeedWriteTimeout = 0;
  HostTimeouts.HighSpeedWritePrespMode = DSI_HS_PM_DISABLE;
  HostTimeouts.LowPowerWriteTimeout = 0;
  HostTimeouts.BTATimeout = 0;
  if (HAL_DSI_ConfigHostTimeouts(&hdsi, &HostTimeouts) != HAL_OK)
  {
    Error_Handler();
  }
  PhyTimings.ClockLaneHS2LPTime = 28;
  PhyTimings.ClockLaneLP2HSTime = 33;
  PhyTimings.DataLaneHS2LPTime = 15;
  PhyTimings.DataLaneLP2HSTime = 25;
  PhyTimings.DataLaneMaxReadTime = 0;
  PhyTimings.StopWaitTime = 10;
  if (HAL_DSI_ConfigPhyTimer(&hdsi, &PhyTimings) != HAL_OK)
  {
    Error_Handler();
  }
  if (HAL_DSI_ConfigFlowControl(&hdsi, DSI_FLOW_CONTROL_BTA) != HAL_OK)
  {
    Error_Handler();
  }
  if (HAL_DSI_SetLowPowerRXFilter(&hdsi, 10000) != HAL_OK)
  {
    Error_Handler();
  }
  if (HAL_DSI_ConfigErrorMonitor(&hdsi, HAL_DSI_ERROR_NONE) != HAL_OK)
  {
    Error_Handler();
  }
  LPCmd.LPGenShortWriteNoP = DSI_LP_GSW0P_ENABLE;
  LPCmd.LPGenShortWriteOneP = DSI_LP_GSW1P_ENABLE;
  LPCmd.LPGenShortWriteTwoP = DSI_LP_GSW2P_ENABLE;
  LPCmd.LPGenShortReadNoP = DSI_LP_GSR0P_ENABLE;
  LPCmd.LPGenShortReadOneP = DSI_LP_GSR1P_ENABLE;
  LPCmd.LPGenShortReadTwoP = DSI_LP_GSR2P_ENABLE;
  LPCmd.LPGenLongWrite = DSI_LP_GLW_ENABLE;
  LPCmd.LPDcsShortWriteNoP = DSI_LP_DSW0P_ENABLE;
  LPCmd.LPDcsShortWriteOneP = DSI_LP_DSW1P_ENABLE;
  LPCmd.LPDcsShortReadNoP = DSI_LP_DSR0P_ENABLE;
  LPCmd.LPDcsLongWrite = DSI_LP_DLW_ENABLE;
  LPCmd.LPMaxReadPacket = DSI_LP_MRDP_ENABLE;
  LPCmd.AcknowledgeRequest = DSI_ACKNOWLEDGE_DISABLE;
  if (HAL_DSI_ConfigCommand(&hdsi, &LPCmd) != HAL_OK)
  {
    Error_Handler();
  }
  CmdCfg.VirtualChannelID = 0;
  CmdCfg.ColorCoding = DSI_RGB888;
  CmdCfg.CommandSize = 400;
  CmdCfg.TearingEffectSource = DSI_TE_EXTERNAL;
  CmdCfg.TearingEffectPolarity = DSI_TE_RISING_EDGE;
  CmdCfg.HSPolarity = DSI_HSYNC_ACTIVE_LOW;
  CmdCfg.VSPolarity = DSI_VSYNC_ACTIVE_LOW;
  CmdCfg.DEPolarity = DSI_DATA_ENABLE_ACTIVE_HIGH;
  CmdCfg.VSyncPol = DSI_VSYNC_FALLING;
  CmdCfg.AutomaticRefresh = DSI_AR_ENABLE;
  CmdCfg.TEAcknowledgeRequest = DSI_TE_ACKNOWLEDGE_ENABLE;
  if (HAL_DSI_ConfigAdaptedCommandMode(&hdsi, &CmdCfg) != HAL_OK)
  {
    Error_Handler();
  }
  if (HAL_DSI_SetGenericVCID(&hdsi, 0) != HAL_OK)
  {
    Error_Handler();
  }

}

static void MX_I2C1_Init(void)
{

  hi2c1.Instance = I2C1;
  hi2c1.Init.Timing = 0x20404768;
  hi2c1.Init.OwnAddress1 = 0;
  hi2c1.Init.AddressingMode = I2C_ADDRESSINGMODE_7BIT;
  hi2c1.Init.DualAddressMode = I2C_DUALADDRESS_DISABLE;
  hi2c1.Init.OwnAddress2 = 0;
  hi2c1.Init.OwnAddress2Masks = I2C_OA2_NOMASK;
  hi2c1.Init.GeneralCallMode = I2C_GENERALCALL_DISABLE;
  hi2c1.Init.NoStretchMode = I2C_NOSTRETCH_DISABLE;
  if (HAL_I2C_Init(&hi2c1) != HAL_OK)
  {
    Error_Handler();
  }

  /** Configure Analogue filter
  */
  if (HAL_I2CEx_ConfigAnalogFilter(&hi2c1, I2C_ANALOGFILTER_ENABLE) != HAL_OK)
  {
    Error_Handler();
  }

  /** Configure Digital filter
  */
  if (HAL_I2CEx_ConfigDigitalFilter(&hi2c1, 0) != HAL_OK)
  {
    Error_Handler();
  }

}

static void MX_I2C4_Init(void)
{

  hi2c4.Instance = I2C4;
  hi2c4.Init.Timing = 0x20404768;
  hi2c4.Init.OwnAddress1 = 0;
  hi2c4.Init.AddressingMode = I2C_ADDRESSINGMODE_7BIT;
  hi2c4.Init.DualAddressMode = I2C_DUALADDRESS_DISABLE;
  hi2c4.Init.OwnAddress2 = 0;
  hi2c4.Init.OwnAddress2Masks = I2C_OA2_NOMASK;
  hi2c4.Init.GeneralCallMode = I2C_GENERALCALL_DISABLE;
  hi2c4.Init.NoStretchMode = I2C_NOSTRETCH_DISABLE;
  if (HAL_I2C_Init(&hi2c4) != HAL_OK)
  {
    Error_Handler();
  }

  /** Configure Analogue filter
  */
  if (HAL_I2CEx_ConfigAnalogFilter(&hi2c4, I2C_ANALOGFILTER_ENABLE) != HAL_OK)
  {
    Error_Handler();
  }

  /** Configure Digital filter
  */
  if (HAL_I2CEx_ConfigDigitalFilter(&hi2c4, 0) != HAL_OK)
  {
    Error_Handler();
  }

}

static void MX_LTDC_Init(void)
{

  LTDC_LayerCfgTypeDef pLayerCfg = {0};

  hltdc.Instance = LTDC;
  hltdc.Init.HSPolarity = LTDC_HSPOLARITY_AL;
  hltdc.Init.VSPolarity = LTDC_VSPOLARITY_AL;
  hltdc.Init.DEPolarity = LTDC_DEPOLARITY_AL;
  hltdc.Init.PCPolarity = LTDC_PCPOLARITY_IPC;
  hltdc.Init.HorizontalSync = 0;
  hltdc.Init.VerticalSync = 0;
  hltdc.Init.AccumulatedHBP = 1;
  hltdc.Init.AccumulatedVBP = 1;
  hltdc.Init.AccumulatedActiveW = 201;
  hltdc.Init.AccumulatedActiveH = 481;
  hltdc.Init.TotalWidth = 202;
  hltdc.Init.TotalHeigh = 482;
  hltdc.Init.Backcolor.Blue = 0;
  hltdc.Init.Backcolor.Green = 0;
  hltdc.Init.Backcolor.Red = 0;
  if (HAL_LTDC_Init(&hltdc) != HAL_OK)
  {
    Error_Handler();
  }
  pLayerCfg.WindowX0 = 0;
  pLayerCfg.WindowX1 = 200;
  pLayerCfg.WindowY0 = 0;
  pLayerCfg.WindowY1 = 480;
  pLayerCfg.PixelFormat = LTDC_PIXEL_FORMAT_RGB565;
  pLayerCfg.Alpha = 255;
  pLayerCfg.Alpha0 = 0;
  pLayerCfg.BlendingFactor1 = LTDC_BLENDING_FACTOR1_PAxCA;
  pLayerCfg.BlendingFactor2 = LTDC_BLENDING_FACTOR2_PAxCA;
  pLayerCfg.FBStartAdress = 0xC0000000;
  pLayerCfg.ImageWidth = 200;
  pLayerCfg.ImageHeight = 480;
  pLayerCfg.Backcolor.Blue = 0;
  pLayerCfg.Backcolor.Green = 0;
  pLayerCfg.Backcolor.Red = 0;
  if (HAL_LTDC_ConfigLayer(&hltdc, &pLayerCfg, 0) != HAL_OK)
  {
    Error_Handler();
  }

}

static void MX_QUADSPI_Init(void)
{

  /* QUADSPI parameter configuration*/
  hqspi.Instance = QUADSPI;
  hqspi.Init.ClockPrescaler = 1;
  hqspi.Init.FifoThreshold = 16;
  hqspi.Init.SampleShifting = QSPI_SAMPLE_SHIFTING_HALFCYCLE;
  hqspi.Init.FlashSize = 26;
  hqspi.Init.ChipSelectHighTime = QSPI_CS_HIGH_TIME_4_CYCLE;
  hqspi.Init.ClockMode = QSPI_CLOCK_MODE_0;
  hqspi.Init.FlashID = QSPI_FLASH_ID_1;
  hqspi.Init.DualFlash = QSPI_DUALFLASH_DISABLE;
  if (HAL_QSPI_Init(&hqspi) != HAL_OK)
  {
    Error_Handler();
  }

}

static void MX_SAI1_Init(void)
{

  hsai_BlockA1.Instance = SAI1_Block_A;
  hsai_BlockA1.Init.Protocol = SAI_FREE_PROTOCOL;
  hsai_BlockA1.Init.AudioMode = SAI_MODEMASTER_TX;
  hsai_BlockA1.Init.DataSize = SAI_DATASIZE_8;
  hsai_BlockA1.Init.FirstBit = SAI_FIRSTBIT_MSB;
  hsai_BlockA1.Init.ClockStrobing = SAI_CLOCKSTROBING_FALLINGEDGE;
  hsai_BlockA1.Init.Synchro = SAI_ASYNCHRONOUS;
  hsai_BlockA1.Init.OutputDrive = SAI_OUTPUTDRIVE_DISABLE;
  hsai_BlockA1.Init.NoDivider = SAI_MASTERDIVIDER_ENABLE;
  hsai_BlockA1.Init.FIFOThreshold = SAI_FIFOTHRESHOLD_EMPTY;
  hsai_BlockA1.Init.AudioFrequency = SAI_AUDIO_FREQUENCY_192K;
  hsai_BlockA1.Init.SynchroExt = SAI_SYNCEXT_DISABLE;
  hsai_BlockA1.Init.MonoStereoMode = SAI_STEREOMODE;
  hsai_BlockA1.Init.CompandingMode = SAI_NOCOMPANDING;
  hsai_BlockA1.Init.TriState = SAI_OUTPUT_NOTRELEASED;
  hsai_BlockA1.FrameInit.FrameLength = 8;
  hsai_BlockA1.FrameInit.ActiveFrameLength = 1;
  hsai_BlockA1.FrameInit.FSDefinition = SAI_FS_STARTFRAME;
  hsai_BlockA1.FrameInit.FSPolarity = SAI_FS_ACTIVE_LOW;
  hsai_BlockA1.FrameInit.FSOffset = SAI_FS_FIRSTBIT;
  hsai_BlockA1.SlotInit.FirstBitOffset = 0;
  hsai_BlockA1.SlotInit.SlotSize = SAI_SLOTSIZE_DATASIZE;
  hsai_BlockA1.SlotInit.SlotNumber = 1;
  hsai_BlockA1.SlotInit.SlotActive = 0x00000000;
  if (HAL_SAI_Init(&hsai_BlockA1) != HAL_OK)
  {
    Error_Handler();
  }
  hsai_BlockB1.Instance = SAI1_Block_B;
  hsai_BlockB1.Init.Protocol = SAI_FREE_PROTOCOL;
  hsai_BlockB1.Init.AudioMode = SAI_MODESLAVE_RX;
  hsai_BlockB1.Init.DataSize = SAI_DATASIZE_8;
  hsai_BlockB1.Init.FirstBit = SAI_FIRSTBIT_MSB;
  hsai_BlockB1.Init.ClockStrobing = SAI_CLOCKSTROBING_FALLINGEDGE;
  hsai_BlockB1.Init.Synchro = SAI_SYNCHRONOUS;
  hsai_BlockB1.Init.OutputDrive = SAI_OUTPUTDRIVE_DISABLE;
  hsai_BlockB1.Init.FIFOThreshold = SAI_FIFOTHRESHOLD_EMPTY;
  hsai_BlockB1.Init.SynchroExt = SAI_SYNCEXT_DISABLE;
  hsai_BlockB1.Init.MonoStereoMode = SAI_STEREOMODE;
  hsai_BlockB1.Init.CompandingMode = SAI_NOCOMPANDING;
  hsai_BlockB1.Init.TriState = SAI_OUTPUT_NOTRELEASED;
  hsai_BlockB1.FrameInit.FrameLength = 8;
  hsai_BlockB1.FrameInit.ActiveFrameLength = 1;
  hsai_BlockB1.FrameInit.FSDefinition = SAI_FS_STARTFRAME;
  hsai_BlockB1.FrameInit.FSPolarity = SAI_FS_ACTIVE_LOW;
  hsai_BlockB1.FrameInit.FSOffset = SAI_FS_FIRSTBIT;
  hsai_BlockB1.SlotInit.FirstBitOffset = 0;
  hsai_BlockB1.SlotInit.SlotSize = SAI_SLOTSIZE_DATASIZE;
  hsai_BlockB1.SlotInit.SlotNumber = 1;
  hsai_BlockB1.SlotInit.SlotActive = 0x00000000;
  if (HAL_SAI_Init(&hsai_BlockB1) != HAL_OK)
  {
    Error_Handler();
  }

}

static void MX_SPI2_Init(void)
{

  /* SPI2 parameter configuration*/
  hspi2.Instance = SPI2;
  hspi2.Init.Mode = SPI_MODE_MASTER;
  hspi2.Init.Direction = SPI_DIRECTION_2LINES;
  hspi2.Init.DataSize = SPI_DATASIZE_4BIT;
  hspi2.Init.CLKPolarity = SPI_POLARITY_LOW;
  hspi2.Init.CLKPhase = SPI_PHASE_1EDGE;
  hspi2.Init.NSS = SPI_NSS_HARD_INPUT;
  hspi2.Init.BaudRatePrescaler = SPI_BAUDRATEPRESCALER_2;
  hspi2.Init.FirstBit = SPI_FIRSTBIT_MSB;
  hspi2.Init.TIMode = SPI_TIMODE_DISABLE;
  hspi2.Init.CRCCalculation = SPI_CRCCALCULATION_DISABLE;
  hspi2.Init.CRCPolynomial = 7;
  hspi2.Init.CRCLength = SPI_CRC_LENGTH_DATASIZE;
  hspi2.Init.NSSPMode = SPI_NSS_PULSE_ENABLE;
  if (HAL_SPI_Init(&hspi2) != HAL_OK)
  {
    Error_Handler();
  }

}

static void MX_TIM1_Init(void)
{

  TIM_ClockConfigTypeDef sClockSourceConfig = {0};
  TIM_MasterConfigTypeDef sMasterConfig = {0};

  htim1.Instance = TIM1;
  htim1.Init.Prescaler = 0;
  htim1.Init.CounterMode = TIM_COUNTERMODE_UP;
  htim1.Init.Period = 65535;
  htim1.Init.ClockDivision = TIM_CLOCKDIVISION_DIV1;
  htim1.Init.RepetitionCounter = 0;
  htim1.Init.AutoReloadPreload = TIM_AUTORELOAD_PRELOAD_DISABLE;
  if (HAL_TIM_Base_Init(&htim1) != HAL_OK)
  {
    Error_Handler();
  }
  sClockSourceConfig.ClockSource = TIM_CLOCKSOURCE_INTERNAL;
  if (HAL_TIM_ConfigClockSource(&htim1, &sClockSourceConfig) != HAL_OK)
  {
    Error_Handler();
  }
  sMasterConfig.MasterOutputTrigger = TIM_TRGO_RESET;
  sMasterConfig.MasterOutputTrigger2 = TIM_TRGO2_RESET;
  sMasterConfig.MasterSlaveMode = TIM_MASTERSLAVEMODE_DISABLE;
  if (HAL_TIMEx_MasterConfigSynchronization(&htim1, &sMasterConfig) != HAL_OK)
  {
    Error_Handler();
  }

}

static void MX_TIM3_Init(void)
{

  TIM_MasterConfigTypeDef sMasterConfig = {0};
  TIM_OC_InitTypeDef sConfigOC = {0};

  htim3.Instance = TIM3;
  htim3.Init.Prescaler = 0;
  htim3.Init.CounterMode = TIM_COUNTERMODE_UP;
  htim3.Init.Period = 65535;
  htim3.Init.ClockDivision = TIM_CLOCKDIVISION_DIV1;
  htim3.Init.AutoReloadPreload = TIM_AUTORELOAD_PRELOAD_DISABLE;
  if (HAL_TIM_PWM_Init(&htim3) != HAL_OK)
  {
    Error_Handler();
  }
  sMasterConfig.MasterOutputTrigger = TIM_TRGO_RESET;
  sMasterConfig.MasterSlaveMode = TIM_MASTERSLAVEMODE_DISABLE;
  if (HAL_TIMEx_MasterConfigSynchronization(&htim3, &sMasterConfig) != HAL_OK)
  {
    Error_Handler();
  }
  sConfigOC.OCMode = TIM_OCMODE_PWM1;
  sConfigOC.Pulse = 0;
  sConfigOC.OCPolarity = TIM_OCPOLARITY_HIGH;
  sConfigOC.OCFastMode = TIM_OCFAST_DISABLE;
  if (HAL_TIM_PWM_ConfigChannel(&htim3, &sConfigOC, TIM_CHANNEL_3) != HAL_OK)
  {
    Error_Handler();
  }
  HAL_TIM_MspPostInit(&htim3);

}

static void MX_TIM10_Init(void)
{

  TIM_OC_InitTypeDef sConfigOC = {0};

  htim10.Instance = TIM10;
  htim10.Init.Prescaler = 0;
  htim10.Init.CounterMode = TIM_COUNTERMODE_UP;
  htim10.Init.Period = 65535;
  htim10.Init.ClockDivision = TIM_CLOCKDIVISION_DIV1;
  htim10.Init.AutoReloadPreload = TIM_AUTORELOAD_PRELOAD_DISABLE;
  if (HAL_TIM_Base_Init(&htim10) != HAL_OK)
  {
    Error_Handler();
  }
  if (HAL_TIM_PWM_Init(&htim10) != HAL_OK)
  {
    Error_Handler();
  }
  sConfigOC.OCMode = TIM_OCMODE_PWM1;
  sConfigOC.Pulse = 0;
  sConfigOC.OCPolarity = TIM_OCPOLARITY_HIGH;
  sConfigOC.OCFastMode = TIM_OCFAST_DISABLE;
  if (HAL_TIM_PWM_ConfigChannel(&htim10, &sConfigOC, TIM_CHANNEL_1) != HAL_OK)
  {
    Error_Handler();
  }
  HAL_TIM_MspPostInit(&htim10);

}

static void MX_TIM11_Init(void)
{

  TIM_OC_InitTypeDef sConfigOC = {0};

  htim11.Instance = TIM11;
  htim11.Init.Prescaler = 0;
  htim11.Init.CounterMode = TIM_COUNTERMODE_UP;
  htim11.Init.Period = 65535;
  htim11.Init.ClockDivision = TIM_CLOCKDIVISION_DIV1;
  htim11.Init.AutoReloadPreload = TIM_AUTORELOAD_PRELOAD_DISABLE;
  if (HAL_TIM_Base_Init(&htim11) != HAL_OK)
  {
    Error_Handler();
  }
  if (HAL_TIM_PWM_Init(&htim11) != HAL_OK)
  {
    Error_Handler();
  }
  sConfigOC.OCMode = TIM_OCMODE_PWM1;
  sConfigOC.Pulse = 0;
  sConfigOC.OCPolarity = TIM_OCPOLARITY_HIGH;
  sConfigOC.OCFastMode = TIM_OCFAST_DISABLE;
  if (HAL_TIM_PWM_ConfigChannel(&htim11, &sConfigOC, TIM_CHANNEL_1) != HAL_OK)
  {
    Error_Handler();
  }
  HAL_TIM_MspPostInit(&htim11);

}

static void MX_TIM12_Init(void)
{

  TIM_OC_InitTypeDef sConfigOC = {0};

  htim12.Instance = TIM12;
  htim12.Init.Prescaler = 0;
  htim12.Init.CounterMode = TIM_COUNTERMODE_UP;
  htim12.Init.Period = 65535;
  htim12.Init.ClockDivision = TIM_CLOCKDIVISION_DIV1;
  htim12.Init.AutoReloadPreload = TIM_AUTORELOAD_PRELOAD_DISABLE;
  if (HAL_TIM_PWM_Init(&htim12) != HAL_OK)
  {
    Error_Handler();
  }
  sConfigOC.OCMode = TIM_OCMODE_PWM1;
  sConfigOC.Pulse = 0;
  sConfigOC.OCPolarity = TIM_OCPOLARITY_HIGH;
  sConfigOC.OCFastMode = TIM_OCFAST_DISABLE;
  if (HAL_TIM_PWM_ConfigChannel(&htim12, &sConfigOC, TIM_CHANNEL_1) != HAL_OK)
  {
    Error_Handler();
  }
  HAL_TIM_MspPostInit(&htim12);

}

static void MX_USART1_UART_Init(void)
{

  huart1.Instance = USART1;
  huart1.Init.BaudRate = 115200;
  huart1.Init.WordLength = UART_WORDLENGTH_8B;
  huart1.Init.StopBits = UART_STOPBITS_1;
  huart1.Init.Parity = UART_PARITY_NONE;
  huart1.Init.Mode = UART_MODE_TX_RX;
  huart1.Init.HwFlowCtl = UART_HWCONTROL_NONE;
  huart1.Init.OverSampling = UART_OVERSAMPLING_16;
  huart1.Init.OneBitSampling = UART_ONE_BIT_SAMPLE_DISABLE;
  huart1.AdvancedInit.AdvFeatureInit = UART_ADVFEATURE_NO_INIT;
  if (HAL_UART_Init(&huart1) != HAL_OK)
  {
    Error_Handler();
  }

}

/* FMC initialization function */
static void MX_FMC_Init(void)
{

  FMC_SDRAM_TimingTypeDef SdramTiming = {0};

  /** Perform the SDRAM1 memory initialization sequence
  */
  hsdram1.Instance = FMC_SDRAM_DEVICE;
  /* hsdram1.Init */
  hsdram1.Init.SDBank = FMC_SDRAM_BANK1;
  hsdram1.Init.ColumnBitsNumber = FMC_SDRAM_COLUMN_BITS_NUM_8;
  hsdram1.Init.RowBitsNumber = FMC_SDRAM_ROW_BITS_NUM_12;
  hsdram1.Init.MemoryDataWidth = FMC_SDRAM_MEM_BUS_WIDTH_32;
  hsdram1.Init.InternalBankNumber = FMC_SDRAM_INTERN_BANKS_NUM_4;
  hsdram1.Init.CASLatency = FMC_SDRAM_CAS_LATENCY_3;
  hsdram1.Init.WriteProtection = FMC_SDRAM_WRITE_PROTECTION_DISABLE;
  hsdram1.Init.SDClockPeriod = FMC_SDRAM_CLOCK_PERIOD_2;
  hsdram1.Init.ReadBurst = FMC_SDRAM_RBURST_ENABLE;
  hsdram1.Init.ReadPipeDelay = FMC_SDRAM_RPIPE_DELAY_0;
  /* SdramTiming */
  SdramTiming.LoadToActiveDelay = 2;
  SdramTiming.ExitSelfRefreshDelay = 7;
  SdramTiming.SelfRefreshTime = 4;
  SdramTiming.RowCycleDelay = 7;
  SdramTiming.WriteRecoveryTime = 3;
  SdramTiming.RPDelay = 2;
  SdramTiming.RCDDelay = 2;

  if (HAL_SDRAM_Init(&hsdram1, &SdramTiming) != HAL_OK)
  {
    Error_Handler( );
  }

}

static void MX_GPIO_Init(void)
{
  GPIO_InitTypeDef GPIO_InitStruct = {0};

  /* GPIO Ports Clock Enable */
  __HAL_RCC_GPIOE_CLK_ENABLE();
  __HAL_RCC_GPIOG_CLK_ENABLE();
  __HAL_RCC_GPIOB_CLK_ENABLE();
  __HAL_RCC_GPIOD_CLK_ENABLE();
  __HAL_RCC_GPIOC_CLK_ENABLE();
  __HAL_RCC_GPIOA_CLK_ENABLE();
  __HAL_RCC_GPIOJ_CLK_ENABLE();
  __HAL_RCC_GPIOI_CLK_ENABLE();
  __HAL_RCC_GPIOK_CLK_ENABLE();
  __HAL_RCC_GPIOF_CLK_ENABLE();
  __HAL_RCC_GPIOH_CLK_ENABLE();

  /*Configure GPIO pin Output Level */
  HAL_GPIO_WritePin(GPIOJ, LD_USER1_Pin|DSI_RESET_Pin|LD_USER2_Pin, GPIO_PIN_RESET);

  /*Configure GPIO pins : RMII_TXD1_Pin RMII_TXD0_Pin RMII_TX_EN_Pin */
  GPIO_InitStruct.Pin = RMII_TXD1_Pin|RMII_TXD0_Pin|RMII_TX_EN_Pin;
  GPIO_InitStruct.Mode = GPIO_MODE_AF_PP;
  GPIO_InitStruct.Pull = GPIO_NOPULL;
  GPIO_InitStruct.Speed = GPIO_SPEED_FREQ_VERY_HIGH;
  GPIO_InitStruct.Alternate = GPIO_AF11_ETH;
  HAL_GPIO_Init(GPIOG, &GPIO_InitStruct);

  /*Configure GPIO pins : ULPI_D7_Pin ULPI_D6_Pin ULPI_D5_Pin ULPI_D3_Pin
                           ULPI_D2_Pin ULPI_D1_Pin ULPI_D4_Pin */
  GPIO_InitStruct.Pin = ULPI_D7_Pin|ULPI_D6_Pin|ULPI_D5_Pin|ULPI_D3_Pin
                          |ULPI_D2_Pin|ULPI_D1_Pin|ULPI_D4_Pin;
  GPIO_InitStruct.Mode = GPIO_MODE_AF_PP;
  GPIO_InitStruct.Pull = GPIO_NOPULL;
  GPIO_InitStruct.Speed = GPIO_SPEED_FREQ_VERY_HIGH;
  GPIO_InitStruct.Alternate = GPIO_AF10_OTG_HS;
  HAL_GPIO_Init(GPIOB, &GPIO_InitStruct);

  /*Configure GPIO pins : uSD_D3_Pin uSD_D2_Pin */
  GPIO_InitStruct.Pin = uSD_D3_Pin|uSD_D2_Pin;
  GPIO_InitStruct.Mode = GPIO_MODE_AF_PP;
  GPIO_InitStruct.Pull = GPIO_NOPULL;
  GPIO_InitStruct.Speed = GPIO_SPEED_FREQ_VERY_HIGH;
  GPIO_InitStruct.Alternate = GPIO_AF10_SDMMC2;
  HAL_GPIO_Init(GPIOB, &GPIO_InitStruct);

  /*Configure GPIO pins : uSD_CMD_Pin uSD_CLK_Pin */
  GPIO_InitStruct.Pin = uSD_CMD_Pin|uSD_CLK_Pin;
  GPIO_InitStruct.Mode = GPIO_MODE_AF_PP;
  GPIO_InitStruct.Pull = GPIO_NOPULL;
  GPIO_InitStruct.Speed = GPIO_SPEED_FREQ_VERY_HIGH;
  GPIO_InitStruct.Alternate = GPIO_AF11_SDMMC2;
  HAL_GPIO_Init(GPIOD, &GPIO_InitStruct);

  /*Configure GPIO pin : WIFI_RX_Pin */
  GPIO_InitStruct.Pin = WIFI_RX_Pin;
  GPIO_InitStruct.Mode = GPIO_MODE_AF_PP;
  GPIO_InitStruct.Pull = GPIO_NOPULL;
  GPIO_InitStruct.Speed = GPIO_SPEED_FREQ_VERY_HIGH;
  GPIO_InitStruct.Alternate = GPIO_AF8_UART5;
  HAL_GPIO_Init(WIFI_RX_GPIO_Port, &GPIO_InitStruct);

  /*Configure GPIO pin : CEC_Pin */
  GPIO_InitStruct.Pin = CEC_Pin;
  GPIO_InitStruct.Mode = GPIO_MODE_AF_OD;
  GPIO_InitStruct.Pull = GPIO_NOPULL;
  GPIO_InitStruct.Speed = GPIO_SPEED_FREQ_LOW;
  GPIO_InitStruct.Alternate = GPIO_AF4_CEC;
  HAL_GPIO_Init(CEC_GPIO_Port, &GPIO_InitStruct);

  /*Configure GPIO pins : LD_USER1_Pin DSI_RESET_Pin LD_USER2_Pin */
  GPIO_InitStruct.Pin = LD_USER1_Pin|DSI_RESET_Pin|LD_USER2_Pin;
  GPIO_InitStruct.Mode = GPIO_MODE_OUTPUT_PP;
  GPIO_InitStruct.Pull = GPIO_NOPULL;
  GPIO_InitStruct.Speed = GPIO_SPEED_FREQ_LOW;
  HAL_GPIO_Init(GPIOJ, &GPIO_InitStruct);

  /*Configure GPIO pins : Audio_INT_Pin WIFI_RST_Pin ARD_D8_Pin ARD_D7_Pin
                           ARD_D4_Pin ARD_D2_Pin */
  GPIO_InitStruct.Pin = Audio_INT_Pin|WIFI_RST_Pin|ARD_D8_Pin|ARD_D7_Pin
                          |ARD_D4_Pin|ARD_D2_Pin;
  GPIO_InitStruct.Mode = GPIO_MODE_INPUT;
  GPIO_InitStruct.Pull = GPIO_NOPULL;
  HAL_GPIO_Init(GPIOJ, &GPIO_InitStruct);

  /*Configure GPIO pin : DFSDM_DATIN5_Pin */
  GPIO_InitStruct.Pin = DFSDM_DATIN5_Pin;
  GPIO_InitStruct.Mode = GPIO_MODE_AF_PP;
  GPIO_InitStruct.Pull = GPIO_NOPULL;
  GPIO_InitStruct.Speed = GPIO_SPEED_FREQ_LOW;
  GPIO_InitStruct.Alternate = GPIO_AF3_DFSDM1;
  HAL_GPIO_Init(DFSDM_DATIN5_GPIO_Port, &GPIO_InitStruct);

  /*Configure GPIO pins : NC4_Pin NC5_Pin uSD_Detect_Pin LCD_BL_CTRL_Pin */
  GPIO_InitStruct.Pin = NC4_Pin|NC5_Pin|uSD_Detect_Pin|LCD_BL_CTRL_Pin;
  GPIO_InitStruct.Mode = GPIO_MODE_INPUT;
  GPIO_InitStruct.Pull = GPIO_NOPULL;
  HAL_GPIO_Init(GPIOI, &GPIO_InitStruct);

  /*Configure GPIO pins : NC3_Pin NC2_Pin NC1_Pin NC8_Pin
                           NC7_Pin */
  GPIO_InitStruct.Pin = NC3_Pin|NC2_Pin|NC1_Pin|NC8_Pin
                          |NC7_Pin;
  GPIO_InitStruct.Mode = GPIO_MODE_INPUT;
  GPIO_InitStruct.Pull = GPIO_NOPULL;
  HAL_GPIO_Init(GPIOK, &GPIO_InitStruct);

  /*Configure GPIO pin : SPDIF_RX_Pin */
  GPIO_InitStruct.Pin = SPDIF_RX_Pin;
  GPIO_InitStruct.Mode = GPIO_MODE_AF_PP;
  GPIO_InitStruct.Pull = GPIO_NOPULL;
  GPIO_InitStruct.Speed = GPIO_SPEED_FREQ_LOW;
  GPIO_InitStruct.Alternate = GPIO_AF7_SPDIFRX;
  HAL_GPIO_Init(SPDIF_RX_GPIO_Port, &GPIO_InitStruct);

  /*Configure GPIO pins : uSD_D1_Pin uSD_D0_Pin */
  GPIO_InitStruct.Pin = uSD_D1_Pin|uSD_D0_Pin;
  GPIO_InitStruct.Mode = GPIO_MODE_AF_PP;
  GPIO_InitStruct.Pull = GPIO_NOPULL;
  GPIO_InitStruct.Speed = GPIO_SPEED_FREQ_VERY_HIGH;
  GPIO_InitStruct.Alternate = GPIO_AF11_SDMMC2;
  HAL_GPIO_Init(GPIOG, &GPIO_InitStruct);

  /*Configure GPIO pins : RMII_RXER_Pin OTG_FS_OverCurrent_Pin */
  GPIO_InitStruct.Pin = RMII_RXER_Pin|OTG_FS_OverCurrent_Pin;
  GPIO_InitStruct.Mode = GPIO_MODE_INPUT;
  GPIO_InitStruct.Pull = GPIO_NOPULL;
  HAL_GPIO_Init(GPIOD, &GPIO_InitStruct);

  /*Configure GPIO pin : DFSDM_CKOUT_Pin */
  GPIO_InitStruct.Pin = DFSDM_CKOUT_Pin;
  GPIO_InitStruct.Mode = GPIO_MODE_AF_PP;
  GPIO_InitStruct.Pull = GPIO_NOPULL;
  GPIO_InitStruct.Speed = GPIO_SPEED_FREQ_LOW;
  GPIO_InitStruct.Alternate = GPIO_AF3_DFSDM1;
  HAL_GPIO_Init(DFSDM_CKOUT_GPIO_Port, &GPIO_InitStruct);

  /*Configure GPIO pin : PC13 */
  GPIO_InitStruct.Pin = GPIO_PIN_13;
  GPIO_InitStruct.Mode = GPIO_MODE_AF_PP;
  GPIO_InitStruct.Pull = GPIO_NOPULL;
  GPIO_InitStruct.Speed = GPIO_SPEED_FREQ_LOW;
  HAL_GPIO_Init(GPIOC, &GPIO_InitStruct);

  /*Configure GPIO pin : WIFI_TX_Pin */
  GPIO_InitStruct.Pin = WIFI_TX_Pin;
  GPIO_InitStruct.Mode = GPIO_MODE_AF_PP;
  GPIO_InitStruct.Pull = GPIO_NOPULL;
  GPIO_InitStruct.Speed = GPIO_SPEED_FREQ_VERY_HIGH;
  GPIO_InitStruct.Alternate = GPIO_AF8_UART5;
  HAL_GPIO_Init(WIFI_TX_GPIO_Port, &GPIO_InitStruct);

  /*Configure GPIO pin : ULPI_DIR_Pin */
  GPIO_InitStruct.Pin = ULPI_DIR_Pin;
  GPIO_InitStruct.Mode = GPIO_MODE_AF_PP;
  GPIO_InitStruct.Pull = GPIO_NOPULL;
  GPIO_InitStruct.Speed = GPIO_SPEED_FREQ_VERY_HIGH;
  GPIO_InitStruct.Alternate = GPIO_AF10_OTG_HS;
  HAL_GPIO_Init(ULPI_DIR_GPIO_Port, &GPIO_InitStruct);

  /*Configure GPIO pin : CEC_CLK_Pin */
  GPIO_InitStruct.Pin = CEC_CLK_Pin;
  GPIO_InitStruct.Mode = GPIO_MODE_AF_PP;
  GPIO_InitStruct.Pull = GPIO_NOPULL;
  GPIO_InitStruct.Speed = GPIO_SPEED_FREQ_LOW;
  GPIO_InitStruct.Alternate = GPIO_AF0_MCO;
  HAL_GPIO_Init(CEC_CLK_GPIO_Port, &GPIO_InitStruct);

  /*Configure GPIO pin : LCD_INT_Pin */
  GPIO_InitStruct.Pin = LCD_INT_Pin;
  GPIO_InitStruct.Mode = GPIO_MODE_EVT_RISING;
  GPIO_InitStruct.Pull = GPIO_NOPULL;
  HAL_GPIO_Init(LCD_INT_GPIO_Port, &GPIO_InitStruct);

  /*Configure GPIO pins : ARD_D0_RX_Pin ARDUINO_TX_D1_Pin */
  GPIO_InitStruct.Pin = ARD_D0_RX_Pin|ARDUINO_TX_D1_Pin;
  GPIO_InitStruct.Mode = GPIO_MODE_AF_PP;
  GPIO_InitStruct.Pull = GPIO_NOPULL;
  GPIO_InitStruct.Speed = GPIO_SPEED_FREQ_VERY_HIGH;
  GPIO_InitStruct.Alternate = GPIO_AF8_USART6;
  HAL_GPIO_Init(GPIOC, &GPIO_InitStruct);

  /*Configure GPIO pin : ULPI_NXT_Pin */
  GPIO_InitStruct.Pin = ULPI_NXT_Pin;
  GPIO_InitStruct.Mode = GPIO_MODE_AF_PP;
  GPIO_InitStruct.Pull = GPIO_NOPULL;
  GPIO_InitStruct.Speed = GPIO_SPEED_FREQ_VERY_HIGH;
  GPIO_InitStruct.Alternate = GPIO_AF10_OTG_HS;
  HAL_GPIO_Init(ULPI_NXT_GPIO_Port, &GPIO_InitStruct);

  /*Configure GPIO pins : EXT_SDA_Pin EXT_SCL_Pin */
  GPIO_InitStruct.Pin = EXT_SDA_Pin|EXT_SCL_Pin;
  GPIO_InitStruct.Mode = GPIO_MODE_INPUT;
  GPIO_InitStruct.Pull = GPIO_NOPULL;
  HAL_GPIO_Init(GPIOG, &GPIO_InitStruct);

  /*Configure GPIO pins : ARDUINO_A1_Pin ARDUINO_A2_Pin ARDUINO_A3_Pin */
  GPIO_InitStruct.Pin = ARDUINO_A1_Pin|ARDUINO_A2_Pin|ARDUINO_A3_Pin;
  GPIO_InitStruct.Mode = GPIO_MODE_ANALOG;
  GPIO_InitStruct.Pull = GPIO_NOPULL;
  HAL_GPIO_Init(GPIOF, &GPIO_InitStruct);

  /*Configure GPIO pin : ULPI_STP_Pin */
  GPIO_InitStruct.Pin = ULPI_STP_Pin;
  GPIO_InitStruct.Mode = GPIO_MODE_AF_PP;
  GPIO_InitStruct.Pull = GPIO_NOPULL;
  GPIO_InitStruct.Speed = GPIO_SPEED_FREQ_VERY_HIGH;
  GPIO_InitStruct.Alternate = GPIO_AF10_OTG_HS;
  HAL_GPIO_Init(ULPI_STP_GPIO_Port, &GPIO_InitStruct);

  /*Configure GPIO pins : RMII_MDC_Pin RMII_RXD0_Pin RMII_RXD1_Pin */
  GPIO_InitStruct.Pin = RMII_MDC_Pin|RMII_RXD0_Pin|RMII_RXD1_Pin;
  GPIO_InitStruct.Mode = GPIO_MODE_AF_PP;
  GPIO_InitStruct.Pull = GPIO_NOPULL;
  GPIO_InitStruct.Speed = GPIO_SPEED_FREQ_VERY_HIGH;
  GPIO_InitStruct.Alternate = GPIO_AF11_ETH;
  HAL_GPIO_Init(GPIOC, &GPIO_InitStruct);

  /*Configure GPIO pin : ARD_A2_Pin */
  GPIO_InitStruct.Pin = ARD_A2_Pin;
  GPIO_InitStruct.Mode = GPIO_MODE_ANALOG;
  GPIO_InitStruct.Pull = GPIO_NOPULL;
  HAL_GPIO_Init(ARD_A2_GPIO_Port, &GPIO_InitStruct);

  /*Configure GPIO pins : RMII_REF_CLK_Pin RMII_MDIO_Pin RMII_CRS_DV_Pin */
  GPIO_InitStruct.Pin = RMII_REF_CLK_Pin|RMII_MDIO_Pin|RMII_CRS_DV_Pin;
  GPIO_InitStruct.Mode = GPIO_MODE_AF_PP;
  GPIO_InitStruct.Pull = GPIO_NOPULL;
  GPIO_InitStruct.Speed = GPIO_SPEED_FREQ_VERY_HIGH;
  GPIO_InitStruct.Alternate = GPIO_AF11_ETH;
  HAL_GPIO_Init(GPIOA, &GPIO_InitStruct);

  /*Configure GPIO pin : B_USER_Pin */
  GPIO_InitStruct.Pin = B_USER_Pin;
  GPIO_InitStruct.Mode = GPIO_MODE_IT_RISING;
  GPIO_InitStruct.Pull = GPIO_NOPULL;
  HAL_GPIO_Init(B_USER_GPIO_Port, &GPIO_InitStruct);

  /*Configure GPIO pins : ARD_A1_Pin ARD_A0_Pin */
  GPIO_InitStruct.Pin = ARD_A1_Pin|ARD_A0_Pin;
  GPIO_InitStruct.Mode = GPIO_MODE_ANALOG;
  GPIO_InitStruct.Pull = GPIO_NOPULL;
  HAL_GPIO_Init(GPIOA, &GPIO_InitStruct);

  /*Configure GPIO pin : SPDIF_TX_Pin */
  GPIO_InitStruct.Pin = SPDIF_TX_Pin;
  GPIO_InitStruct.Mode = GPIO_MODE_AF_PP;
  GPIO_InitStruct.Pull = GPIO_NOPULL;
  GPIO_InitStruct.Speed = GPIO_SPEED_FREQ_LOW;
  GPIO_InitStruct.Alternate = GPIO_AF10_SAI2;
  HAL_GPIO_Init(SPDIF_TX_GPIO_Port, &GPIO_InitStruct);

  /*Configure GPIO pin : PH7 */
  GPIO_InitStruct.Pin = GPIO_PIN_7;
  GPIO_InitStruct.Mode = GPIO_MODE_INPUT;
  GPIO_InitStruct.Pull = GPIO_NOPULL;
  HAL_GPIO_Init(GPIOH, &GPIO_InitStruct);

  /*Configure GPIO pins : ULPI_CLK_Pin ULPI_D0_Pin */
  GPIO_InitStruct.Pin = ULPI_CLK_Pin|ULPI_D0_Pin;
  GPIO_InitStruct.Mode = GPIO_MODE_AF_PP;
  GPIO_InitStruct.Pull = GPIO_NOPULL;
  GPIO_InitStruct.Speed = GPIO_SPEED_FREQ_VERY_HIGH;
  GPIO_InitStruct.Alternate = GPIO_AF10_OTG_HS;
  HAL_GPIO_Init(GPIOA, &GPIO_InitStruct);

}

/* USER CODE BEGIN 4 */
int _write(int fd, char * ptr, int len) {

  HAL_UART_Transmit(&huart1, (uint8_t *) ptr, len, HAL_MAX_DELAY);
  return len;
}

/* USER CODE END 4 */

void HAL_TIM_PeriodElapsedCallback(TIM_HandleTypeDef *htim)
{
  if (htim->Instance == TIM6)
  {
    HAL_IncTick();
  }
}

void Error_Handler(void)
{
  __disable_irq();
  while (1)
  {
  }
}
